# a34g43x register map
Vendor: ABOV Semiconductor Co., Ltd.; File version: 1.0
CPU: CM4 r0p1, little endian, MPU, FPU, VTOR, 4 interrupt priority bits
Registers are 32-bit, read-write, reset 0x0 unless marked. A register's access mark holds for its fields unless they carry their own. Offsets are from the block's base; [hi:lo] are bit positions; {n}, {i} and the like mark numbered series; 'fields as' and 'values as' point back to an identical list.

## SCU — System Control Unit
Base 0x40000000
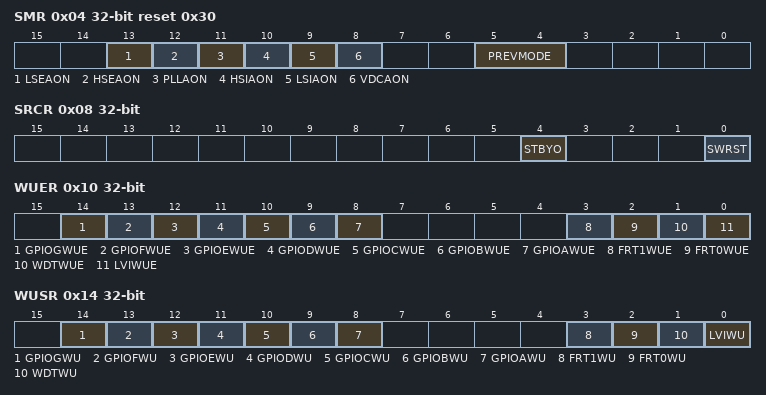
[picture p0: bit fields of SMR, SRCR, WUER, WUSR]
0x04 SMR reset 0x30 — System Mode Register
  [13] LSEAON — Auto LSE operation in power down mode
  [12] HSEAON — Auto HSE operation in power down mode
  [11] PLLAON — Auto PLL operation in power down mode
  [10] HSIAON — Auto HSI operation in power down mode
  [9] LSIAON — Auto LSI operation in power down mode
  [8] VDCAON — Auto VDC operation in power down mode
  [5:4] PREVMODE ro — Previous operation mode in current reset event
    0=RUN_MODE (Previous mode is run); 1=SLEEP_MODE (Previous mode is sleep); 2=POWERDOWN_MODE (Previous mode is powerdown); 3=INIT_MODE (Previous mode is init)
0x08 SRCR — System reset control Register
  [4] STBYO — STBYO pin output polarity selection bit
  [0] SWRST wo — Internal soft reset enable bit
0x10 WUER — Wake-up Source Enable Register
  [14] GPIOGWUE — GPIOG Wake-up source setting
  [13] GPIOFWUE — GPIOF Wake-up source setting
  [12] GPIOEWUE — GPIOE Wake-up source setting
  [11] GPIODWUE — GPIOD Wake-up source setting
  [10] GPIOCWUE — GPIOC Wake-up source setting
  [9] GPIOBWUE — GPIOB Wake-up source setting
  [8] GPIOAWUE — GPIOA Wake-up source setting
  [3] FRT1WUE — FRT1 Wake-up source setting
  [2] FRT0WUE — FRT0 Wake-up source setting
  [1] WDTWUE — WDT Wake-up source setting
  [0] LVIWUE — LVD Wake-up source setting
0x14 WUSR ro — Wake-up Source Status Register
  [14] GPIOGWU — GPIOG Wake-up source status
  [13] GPIOFWU — GPIOF Wake-up source status
  [12] GPIOEWU — GPIOE Wake-up source status
  [11] GPIODWU — GPIOD Wake-up source status
  [10] GPIOCWU — GPIOC Wake-up source status
  [9] GPIOBWU — GPIOB Wake-up source status
  [8] GPIOAWU — GPIOA Wake-up source status
  [3] FRT1WU — FRT1 Wake-up source status
  [2] FRT0WU — FRT0 Wake-up source status
  [1] WDTWU — WDT Wake-up source status
  [0] LVIWU — LVD Wake-up source status
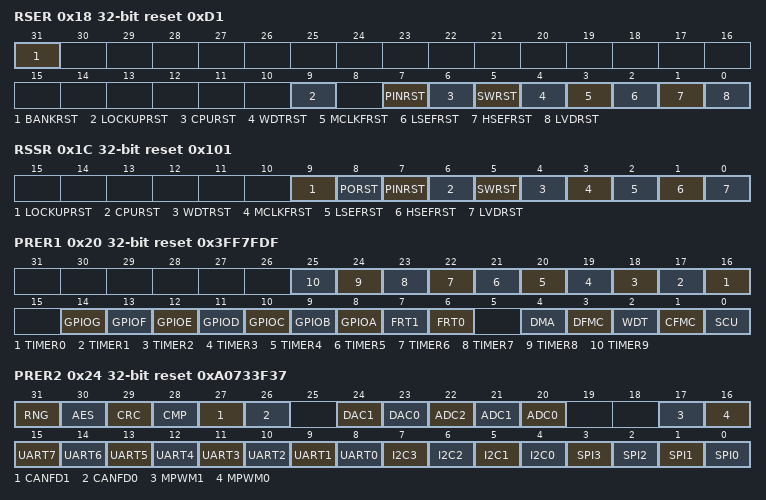
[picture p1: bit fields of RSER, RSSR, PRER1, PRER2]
0x18 RSER reset 0xD1 — Reset Source Enable Register
  [31] BANKRST — Bank reset setting bit
  [9] LOCKUPRST — CPU Lock up reset setting bit
  [7] PINRST — External Pin reset setting bit
  [6] CPURST — CPU request reset setting bit
  [5] SWRST — Software reset setting bit
  [4] WDTRST — WDT reset setting bit
  [3] MCLKFRST — MCLK Clock Fail reset setting bit
  [2] LSEFRST — LSE Clock Fail reset setting bit
  [1] HSEFRST — HSE Clock Fail reset setting bit
  [0] LVDRST — LVD reset setting bit
0x1C RSSR reset 0x101 — Reset Source Status Register
  [9] LOCKUPRST — CPU Lock up reset Status bit
  [8] PORST — POR Status bit
  [7] PINRST — External Pin reset Status bit
  [6] CPURST — CPU request reset Status bit
  [5] SWRST — Software reset Status bit
  [4] WDTRST — WDT reset Status bit
  [3] MCLKFRST — MCLK Clock Fail reset Status bit
  [2] LSEFRST — LSE Clock Fail reset Status bit
  [1] HSEFRST — HSE Clock Fail reset Status bit
  [0] LVDRST — LVD reset Status bit
0x20 PRER1 reset 0x3FF7FDF — Peripheral Reset Enable Register1
  [n+16] TIMER{n} (n=0..9) — TIMER{n} Reset Mask bit
  [14] GPIOG — GPIOG Reset Mask bit
  [13] GPIOF — GPIOF Reset Mask bit
  [12] GPIOE — GPIOE Reset Mask bit
  [11] GPIOD — GPIOD Reset Mask bit
  [10] GPIOC — GPIOC Reset Mask bit
  [9] GPIOB — GPIOB Reset Mask bit
  [8] GPIOA — GPIOA Reset Mask bit
  [7] FRT1 — FRT1 Reset Mask bit
  [6] FRT0 — FRT0 Reset Mask bit
  [4] DMA — DMA Reset Mask bit
  [3] DFMC — DFMC Reset Mask bit
  [2] WDT — WDT Reset Mask bit
  [1] CFMC — CFMC Reset Mask bit
  [0] SCU — SCU Reset Mask bit
0x24 PRER2 reset 0xA0733F37 — Peripheral Reset Enable Register2
  [31] RNG — RNG Reset Mask bit
  [30] AES — AES Reset Mask bit
  [29] CRC — CRC-32 Reset Mask bit
  [28] CMP — Comparator Reset Mask bit
  [27] CANFD1 — CANFD1 Reset Mask bit
  [26] CANFD0 — CANFD0 Reset Mask bit
  [24] DAC1 — DAC1 Reset Mask bit
  [23] DAC0 — DAC0 Reset Mask bit
  [22] ADC2 — ADC2 Reset Mask bit
  [21] ADC1 — ADC1 Reset Mask bit
  [20] ADC0 — ADC0 Reset Mask bit
  [17] MPWM1 — MPWM1 Reset Mask bit
  [16] MPWM0 — MPWM0 Reset Mask bit
  [n+8] UART{n} (n=0..7) — UART{n} Reset Mask bit
  [n+4] I2C{n} (n=0..3) — I2C{n} Reset Mask bit
  [n] SPI{n} (n=0..3) — SPI{n} Reset Mask bit
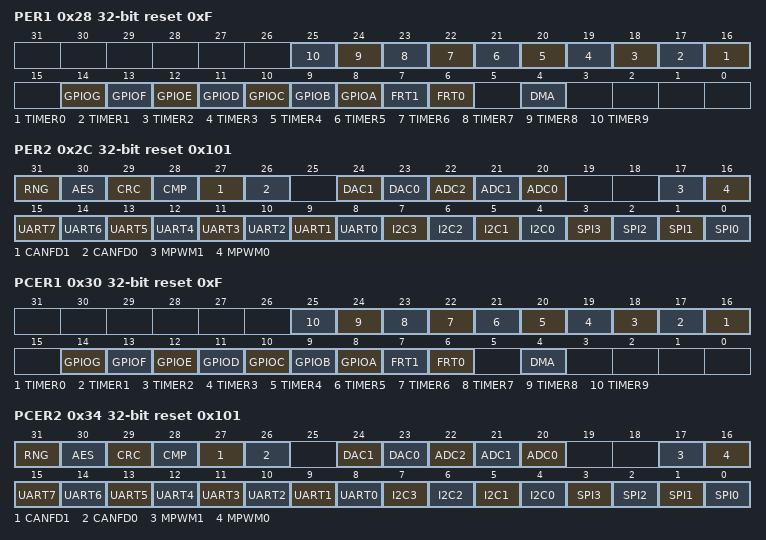
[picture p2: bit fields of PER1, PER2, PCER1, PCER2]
0x28 PER1 reset 0xF — Peripheral Enable Register1
  [n+16] TIMER{n} (n=0..9) — TIMER{n} Enable bit
  [14] GPIOG — GPIOG Enable bit
  [13] GPIOF — GPIOF Enable bit
  [12] GPIOE — GPIOE Enable bit
  [11] GPIOD — GPIOD Enable bit
  [10] GPIOC — GPIOC Enable bit
  [9] GPIOB — GPIOB Enable bit
  [8] GPIOA — GPIOA Enable bit
  [7] FRT1 — FRT1 Enable bit
  [6] FRT0 — FRT0 Enable bit
  [4] DMA — DMA Enable bit
0x2C PER2 reset 0x101 — Peripheral Enable Register2
  [31] RNG — RNG Enable bit
  [30] AES — AES Enable bit
  [29] CRC — CRC32 Enable bit
  [28] CMP — CMP Enable bit
  [27] CANFD1 — CANFD1 Enable bit
  [26] CANFD0 — CANFD0 Enable bit
  [24] DAC1 — DAC1 Enable bit
  [23] DAC0 — DAC0 Enable bit
  [22] ADC2 — ADC2 Enable bit
  [21] ADC1 — ADC1 Enable bit
  [20] ADC0 — ADC0 Enable bit
  [17] MPWM1 — MPWM1 Enable bit
  [16] MPWM0 — MPWM0 Enable bit
  [n+8] UART{n} (n=0..7) — UART{n} Enable bit
  [n+4] I2C{n} (n=0..3) — I2C{n} Enable bit
  [n] SPI{n} (n=0..3) — SPI{n} Enable bit
0x30 PCER1 reset 0xF — Peripheral Clock Enable Register1
  [n+16] TIMER{n} (n=0..9) — TIMER{n} Clock Enable bit
  [14] GPIOG — GPIOG Clock Enable bit
  [13] GPIOF — GPIOF Clock Enable bit
  [12] GPIOE — GPIOE Clock Enable bit
  [11] GPIOD — GPIOD Clock Enable bit
  [10] GPIOC — GPIOC Clock Enable bit
  [9] GPIOB — GPIOB Clock Enable bit
  [8] GPIOA — GPIOA Clock Enable bit
  [7] FRT1 — FRT1 Clock Enable bit
  [6] FRT0 — FRT0 Clock Enable bit
  [4] DMA — DMA Clock Enable bit
0x34 PCER2 reset 0x101 — Peripheral Clock Enable Register2
  [31] RNG — RNG Clock Enable bit
  [30] AES — AES Clock Enable bit
  [29] CRC — CRC32 Clock Enable bit
  [28] CMP — Comparator Clock Enable bit
  [27] CANFD1 — CANFD1 Clock Enable bit
  [26] CANFD0 — CANFD0 Clock Enable bit
  [24] DAC1 — DAC1 Clock Enable bit
  [23] DAC0 — DAC0 Clock Enable bit
  [22] ADC2 — ADC2 Clock Enable bit
  [21] ADC1 — ADC1 Clock Enable bit
  [20] ADC0 — ADC0 Clock Enable bit
  [17] MPWM1 — MPWM1 Clock Enable bit
  [16] MPWM0 — MPWM0 Clock Enable bit
  [n+8] UART{n} (n=0..7) — UART{n} Clock Enable bit
  [n+4] I2C{n} (n=0..3) — I2C{n} Clock Enable bit
  [n] SPI{n} (n=0..3) — SPI{n} Clock Enable bit
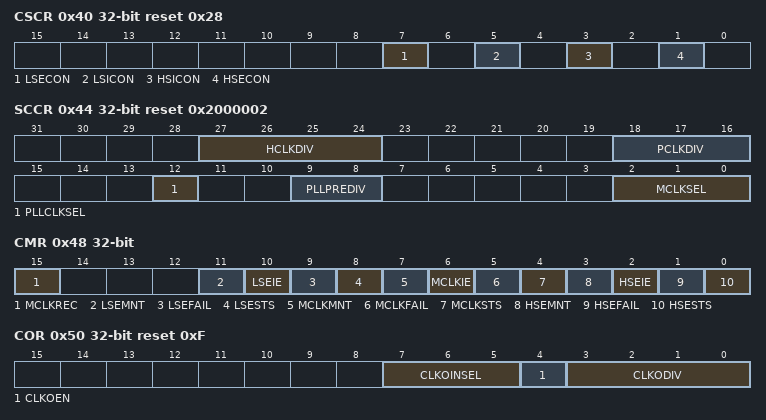
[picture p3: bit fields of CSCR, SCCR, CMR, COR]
0x40 CSCR reset 0x28 — Clock Source Control Register
  [7] LSECON — Low Speed External Sub Crystal Control bit
  [5] LSICON — Low Speed Internal Ring Oscillator Control bit
  [3] HSICON — High Speed Internal Oscillator Control bit
  [1] HSECON — High Speed External Main Crystal Control bit
0x44 SCCR reset 0x2000002 — System clock control register
  [27:24] HCLKDIV — HCLK input clock divide bit
    9=MCLK_DIV_BY_512 (HCLK=MCLK_div_512); 8=MCLK_DIV_BY_256 (HCLK=MCLK_div_256); 7=MCLK_DIV_BY_128 (HCLK=MCLK_div_128); 6=MCLK_DIV_BY_64 (HCLK=MCLK_div_64); 5=MCLK_DIV_BY_32 (HCLK=MCLK_div_32); 4=MCLK_DIV_BY_16 (HCLK=MCLK_div_16); 3=MCLK_DIV_BY_8 (HCLK=MCLK_div_8); 2=MCLK_DIV_BY_4 (HCLK=MCLK_div_4); 1=MCLK_DIV_BY_2 (HCLK=MCLK_div_2); 0=MCLK_DIV_BY_1 (HCLK=MCLK_div_1)
  [18:16] PCLKDIV — PCLK input clock divide bit
    4=HCLK_DIV_BY_16 (PCLK=HCLK_div_16); 3=HCLK_DIV_BY_8 (PCLK=HCLK_div_8); 2=HCLK_DIV_BY_4 (PCLK=HCLK_div_4); 1=HCLK_DIV_BY_2 (PCLK=HCLK_div_2); 0=MCLK_DIV_BY_1 (HCLK=MCLK_div_1)
  [12] PLLCLKSEL — PLL Input clock selection bit
  [9:8] PLLPREDIV — PLL Input clock divide bit
    3=PLLCLKSEL_DIV_BY_8 (PLL Input clock div 8); 2=PLLCLKSEL_DIV_BY_4 (PLL Input clock div 4); 1=PLLCLKSEL_DIV_BY_2 (PLL Input clock div 2); 0=PLLCLKSEL_DIV_BY_1 (PLL Input clock div 1)
  [2:0] MCLKSEL — System Clock Selection bit
    7=PLL (system clock is PLL); 6=HSE (system clock is HSE); 2=HSI (system clock is HSI); 1=LSE (system clock is LSE); 0=LSI (system clock is LSI)
0x48 CMR — Clock Monitoring Register
  [15] MCLKREC — MCLK auto recovery
  [11] LSEMNT — LSE Monitoring Enable bit
  [10] LSEIE — LSE Fail Interrupt Enable bit
  [9] LSEFAIL — LSE Fail Interrupt Flag bit
  [8] LSESTS ro — LSE Status bit
  [7] MCLKMNT — MCLK Monitoring Enable bit
  [6] MCLKIE — MCLK Fail Interrupt Enable bit
  [5] MCLKFAIL — MCLK Fail Interrupt Flag bit
  [4] MCLKSTS ro — MCLK Status bit
  [3] HSEMNT — HSE Monitoring Enable bit
  [2] HSEIE — HSE Fail Interrupt Enable bit
  [1] HSEFAIL — HSE Fail Interrupt Flag bit
  [0] HSESTS ro — HSE Status bit
0x50 COR reset 0xF — Clock Output Setting Register
  [7:5] CLKOINSEL — Output Clock Selection bit
    7=PLL (Output clock is PLL); 6=HSE (Output clock is HSE); 5=HSI (Output clock is HSI); 4=MCLK (Output clock is MCLK); 1=LSE (Output clock is LSE); 0=LSI (Output clock is LSI)
  [4] CLKOEN — Clock Output Enable bit
  [3:0] CLKODIV — Clock Output divide Setting bit
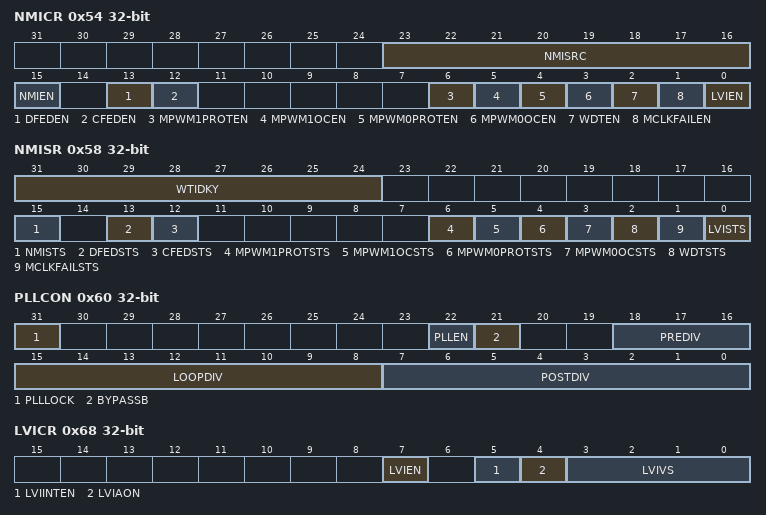
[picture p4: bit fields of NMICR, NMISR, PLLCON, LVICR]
0x54 NMICR — NMI Control Register
  [23:16] NMISRC — NMI Source Selection bits
  [15] NMIEN — NMI Interrupt Enable bit
  [13] DFEDEN — Data Flash ECC Double Error Interrupt Enable bit for NMI Interrupt
  [12] CFEDEN — Code Flash ECC Double Error Interrupt Enable bit for NMI Interrupt
  [6] MPWM1PROTEN — MPWM1 Protection Interrupt Enable bit for NMI Interrupt
  [5] MPWM1OCEN — MPWM1 Over Current Interrupt Enable bit for NMI Interrupt
  [4] MPWM0PROTEN — MPWM0 Protection Interrupt Enable bit for NMI Interrupt
  [3] MPWM0OCEN — MPWM0 Over Current Interrupt Enable bit for NMI Interrupt
  [2] WDTEN — WDT Interrupt Enable bit for NMI Interrupt
  [1] MCLKFAILEN — MCLK Fail Interrupt Enable bit for NMI Interrupt
  [0] LVIEN — LVI Interrupt Enable bit for NMI Interrupt
0x58 NMISR — NMI Status Register
  [31:24] WTIDKY wo — NMI Status Register Write Identification Key (0x8C)
  [15] NMISTS ro — NMI Interrupt Status bit(Not Flag)
  [13] DFEDSTS — Data Flash ECC Double Error Interrupt Status bit
  [12] CFEDSTS — Code Flash ECC Double Error Interrupt Status bit
  [6] MPWM1PROTSTS — MPWM1 Protection Interrupt Status bit
  [5] MPWM1OCSTS — MPWM1 Over Current Interrupt Status bit
  [4] MPWM0PROTSTS — MPWM0 Protection Interrupt Status bit
  [3] MPWM0OCSTS — MPWM0 Over Current Interrupt Status bit
  [2] WDTSTS — WDT Interrupt Status bit
  [1] MCLKFAILSTS — MCLK Fail Interrupt Status bit
  [0] LVISTS — LVI Interrupt Status bit
0x60 PLLCON — PLL Control Register
  [31] PLLLOCK ro — PLL Lock Status Bit
  [22] PLLEN — PLL Enable bit
  [21] BYPASSB — PLL Bypass Bit
  [18:16] PREDIV — FIN Predivider bit
  [15:8] LOOPDIV — PLL Feedback control 1(N1) bit
  [7:0] POSTDIV — PLL Feedback control 2(N2) bit
0x64 VDCCON reset 0x7F — VDC Control Register
  [7:0] VDCWDLY — VDC Warm-up Delay Count Value Bit
0x68 LVICR — Low Voltage Indicator Control Register
  [7] LVIEN — LVI Enable Bit
  [5] LVIINTEN — LVI Interrupt Enable Bit
  [4] LVIAON — LVI Operation Control Bit in Deep Sleep Mode
  [3:0] LVIVS — LVI Voltage Selection Bit
    0=1.57 V; 1=1.66 V; 2=1.78 V; 3=1.88 V; 4=1.99 V; 5=2.11 V; 6=2.28 V; 7=2.43 V; 8=2.66 V; 9=3.00 V; 10=3.14 V; 11=3.53 V; 12=3.71 V; 13=4.03 V; 14=4.21 V; 15=4.47 V
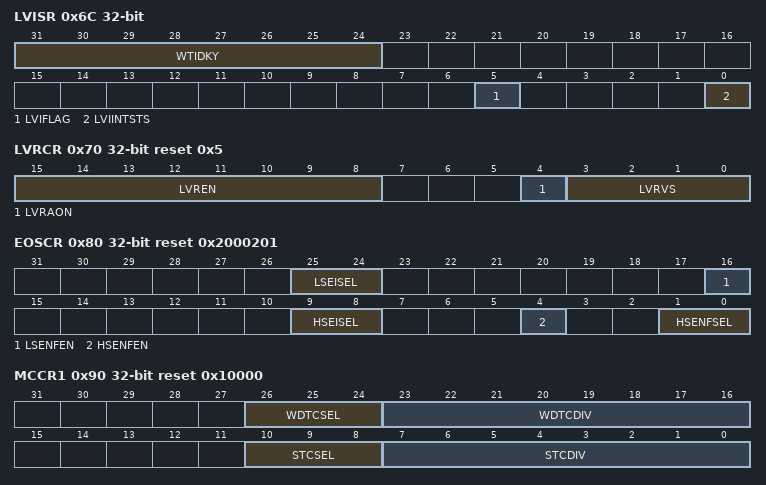
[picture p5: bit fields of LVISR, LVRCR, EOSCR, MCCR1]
0x6C LVISR — Low Voltage Indicator Status Register
  [31:24] WTIDKY wo — LVI Status Write Identification Key (0x7A)
  [5] LVIFLAG — LVI Interrupt Flag Bit
  [0] LVIINTSTS ro — LVI Interrupt Status Bit
0x70 LVRCR reset 0x5 — Low Voltage Reset Control Register
  [15:8] LVREN — LVR Enable Bit, 0xAA : Enable / Others : Disable
  [4] LVRAON — LVR Enable Bit
  [3:0] LVRVS — LVR Voltage Selection Bit
    values as LVICR.LVIVS
0x80 EOSCR reset 0x2000201 — External Oscillator Control Register
  [25:24] LSEISEL — LSE Current Capability Selection
  [16] LSENFEN ro — Must be '1'
  [9:8] HSEISEL — HSE Current Capability Selection
  [4] HSENFEN — HSE Noise Filter Enable Bit
  [1:0] HSENFSEL — HSE Noise Filter Selection
0x90 MCCR1 reset 0x10000 — MISC Clock Control Register1
  [26:24] WDTCSEL — WDT Clock Source Selection Bit
    7=PLL (Clock Source is PLL); 6=HSE (Clock Source is HSE); 5=HSI (Clock Source is HSI); 4=MCLK (Clock Source is MCLK); 1=LSE (Clock Source is LSE); 0=LSI (Clock Source is LSI)
  [23:16] WDTCDIV — WDT Clock N divider
  [10:8] STCSEL — SYSTIC Clock Source Selection Bit
    values as WDTCSEL
  [7:0] STCDIV — SYSTIC Clock N divider
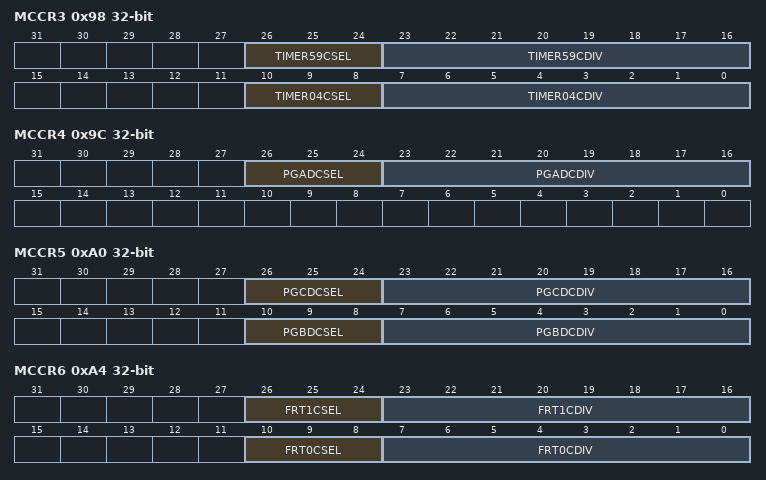
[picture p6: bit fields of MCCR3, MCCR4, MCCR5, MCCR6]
0x98 MCCR3 — MISC Clock Control Register3
  [26:24] TIMER59CSEL — TIMER5-9 Clock Source Selection Bit
    values as MCCR1.WDTCSEL
  [23:16] TIMER59CDIV — TIMER5-9 Clock N divider
  [10:8] TIMER04CSEL — TIMER0-4 Clock Source Selection Bit
    values as MCCR1.WDTCSEL
  [7:0] TIMER04CDIV — TIMER0-4 Clock N divider
0x9C MCCR4 — MISC Clock Control Register4
  [26:24] PGADCSEL — Port A, B Debounce Clock Source Selection Bit
    values as MCCR1.WDTCSEL
  [23:16] PGADCDIV — Port A, B debounce Clock N divider
0xA0 MCCR5 — MISC Clock Control Register5
  [26:24] PGCDCSEL — Port E, F, G Debounce Clock Source Selection Bit
    values as MCCR1.WDTCSEL
  [23:16] PGCDCDIV — Port E, F, G debounce Clock N divider
  [10:8] PGBDCSEL — Port C, D debounce Clock Source Selection Bit
    values as MCCR1.WDTCSEL
  [7:0] PGBDCDIV — Port C, D debounce Clock N divider
0xA4 MCCR6 — MISC Clock Control Register6
  [26:24] FRT1CSEL — FRT1 Clock Source Selection Bit
    values as MCCR1.WDTCSEL
  [23:16] FRT1CDIV — FRT1 Clock N divider
  [10:8] FRT0CSEL — FRT0 Clock Source Selection Bit
    values as MCCR1.WDTCSEL
  [7:0] FRT0CDIV — FRT0 Clock N divider
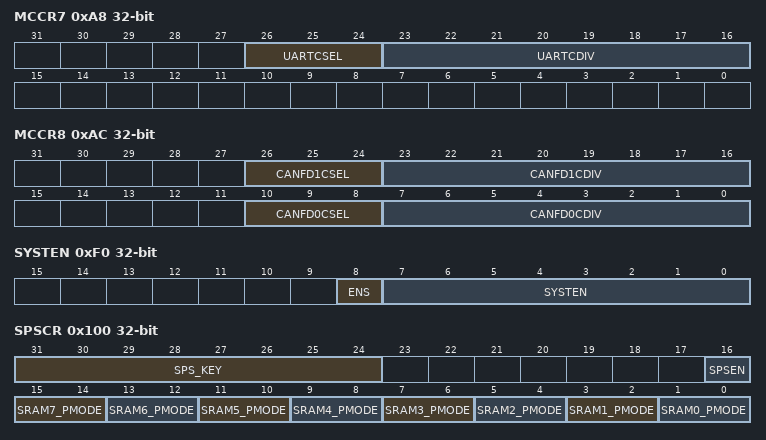
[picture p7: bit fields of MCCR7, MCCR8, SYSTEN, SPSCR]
0xA8 MCCR7 — MISC Clock Control Register7
  [26:24] UARTCSEL — UART Clock Source Selection Bit
    values as MCCR1.WDTCSEL
  [23:16] UARTCDIV — UART Clock N divider
0xAC MCCR8 — MISC Clock Control Register8
  [26:24] CANFD1CSEL — CANFD1 Clock Source Selection Bit
    7=PLL (Clock Source is PLL); 4=MCLK (Clock Source is MCLK)
  [23:16] CANFD1CDIV — CANFD1 Clock N divider
  [10:8] CANFD0CSEL — CANFD0 Clock Source Selection Bit
    7=PLL (Clock Source is PLL); 4=MCLK (Clock Source is MCLK)
  [7:0] CANFD0CDIV — CANFD0 Clock N divider
0xF0 SYSTEN — System Access Key Register
  [8] ENS ro — Enable Status Bit
  [7:0] SYSTEN — System Enable bit
0x100 SPSCR — SRAM Power Sequence Control Register
  [31:24] SPS_KEY wo — SRAM Power Sequence Access Key
  [16] SPSEN wo — Enable SRAM Power Sequence Start bit
  [2n+1:2n] SRAM{n}_PMODE (n=1..7) — SRAM{n} Power Mode
    0=RUN (SRAM{n} run mode); 2=Sleep (SRAM{n} sleep mode); 3=Power_Down (SRAM{n} power down mode)
  [1:0] SRAM0_PMODE ro — SRAM0 Power Mode
    0=RUN (SRAM0 run mode); 2=Sleep (SRAM0 sleep mode); 3=Power_Down (SRAM0 power down mode)
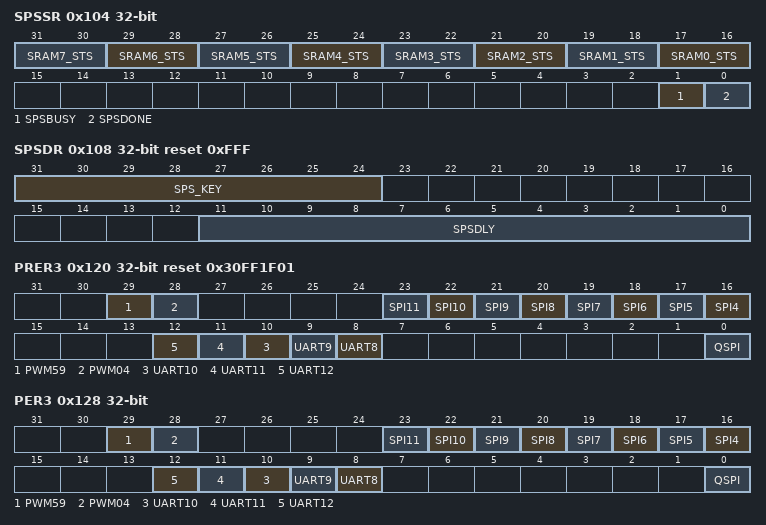
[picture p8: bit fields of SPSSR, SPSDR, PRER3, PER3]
0x104 SPSSR — SRAM Power Sequence Status Register
  [2n+17:2n+16] SRAM{n}_STS ro (n=0..7) — SRAM{n} Power Mode Status
  [1] SPSBUSY ro — SRAM Power Sequence busy check
  [0] SPSDONE — SRAM Power Sequence done status
0x108 SPSDR reset 0xFFF — SRAM Power Sequence Delay Register
  [31:24] SPS_KEY — SRAM Power Sequence Access Key
  [11:0] SPSDLY — SRAM Power Sequence Delay
0x120 PRER3 reset 0x30FF1F01 — Peripheral Reset Enable Register3
  [29] PWM59 — PWM59 Reset Mask bit
  [28] PWM04 — PWM04 Reset Mask bit
  [n+12] SPI{n} (n=4..11) — SPI{n} Reset Mask bit
  [n] UART{n} (n=8..12) — UART{n} Reset Mask bit
  [0] QSPI — QSPI Reset Mask bit
0x128 PER3 — Peripheral Enable Register3
  [29] PWM59 — PWM59 Enable bit
  [28] PWM04 — PWM04 Enable bit
  [n+12] SPI{n} (n=4..11) — SPI{n} Enable bit
  [n] UART{n} (n=8..12) — UART{n} Enable bit
  [0] QSPI — QSPI Enable bit
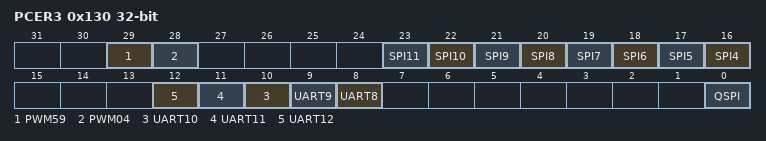
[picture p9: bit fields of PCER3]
0x130 PCER3 — Peripheral Clock Enable Register3
  [29] PWM59 — PWM59 Clock Enable bit
  [28] PWM04 — PWM04 Clock Enable bit
  [n+12] SPI{n} (n=4..11) — SPI{n} Clock Enable bit
  [n] UART{n} (n=8..12) — UART{n} Clock Enable bit
  [0] QSPI — QSPI Clock Enable bit
